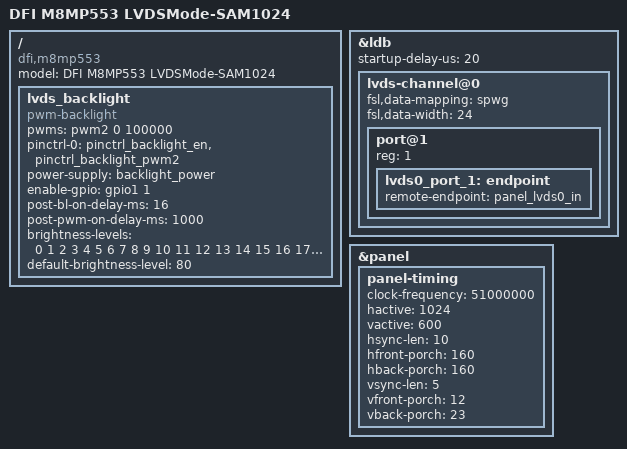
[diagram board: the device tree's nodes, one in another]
// SPDX-License-Identifier: (GPL-2.0+ OR MIT)
/*
 * Copyright 2021 DFI
 * slash.huang@dfi.com
 */

/dts-v1/;

#include "imx8mp-m8mp553.dtsi"

/ {
	model = "DFI M8MP553 LVDSMode-SAM1024";
	compatible = "dfi,m8mp553", "fsl,imx8mp";

	lvds_backlight: lvds_backlight {
		compatible = "pwm-backlight";
		pwms = <&pwm2 0 100000>; /* 10KHz*/
		status = "okay";
		pinctrl-0 = <&pinctrl_backlight_en>, <&pinctrl_backlight_pwm2>;
		power-supply = <&backlight_power>;
		enable-gpio = <&gpio1 1 GPIO_ACTIVE_HIGH>;
		post-bl-on-delay-ms = <16>;
		post-pwm-on-delay-ms = <1000>;
		brightness-levels = < 0  1  2  3  4  5  6  7  8  9
				     10 11 12 13 14 15 16 17 18 19
				     20 21 22 23 24 25 26 27 28 29
				     30 31 32 33 34 35 36 37 38 39
				     40 41 42 43 44 45 46 47 48 49
				     50 51 52 53 54 55 56 57 58 59
				     60 61 62 63 64 65 66 67 68 69
				     70 71 72 73 74 75 76 77 78 79
				     80 81 82 83 84 85 86 87 88 89
				     90 91 92 93 94 95 96 97 98 99
				    100>;
		default-brightness-level = <80>;
	};
};

&ldb {
	status = "okay";
	startup-delay-us = <20>;
	lvds-channel@0 {
		fsl,data-mapping = "spwg";
		fsl,data-width = <24>;
		status = "okay";

		port@1 {
			reg = <1>;
			lvds0_port_1: endpoint {
					remote-endpoint = <&panel_lvds0_in>;
			};
		};
	};
};

&panel {
	status = "okay";
	panel-timing {
		/* 1024x600 @60Hz : AM-1024600DTZQW-TD1H */
		clock-frequency = <51000000>;
		hactive = <1024>;
		vactive = <600>;
		hsync-len = <10>;
		hfront-porch = <160>;
		hback-porch = <160>;
		vsync-len = <5>;
		vfront-porch = <12>;
		vback-porch = <23>;
	};
};
